AUTOSAR XML (schema 00048)
package /myproject/Application/Executable
  executable IAMApp01Exe: category=APPLICATION_LEVEL, build-type=BUILD-TYPE-DEBUG, logging-behavior=USES-LOGGING, reporting-behavior=REPORTS-EXECUTION-STATE
    root sw component prototype RootSwComponent: application-type=IAMApp01
package /myproject/Application/Process
  process IAMApp01_process: design=IAMApp01_processDesign, executable=IAMApp01Exe, log-trace-default-log-level=DEBUG, log-trace-file-path=/adar/install/var/log_apps/ECU1/IAMApp01, log-trace-log-modes=[CONSOLE, FILE, NETWORK], log-trace-process-desc=IAMApp01, log-trace-process-id=IAM1, state-dependent-startup-config{function-group-state=MachineState.Driving, startup-config=startup_config}
    process state machine ProcessStateMachine: type=ProcessState
package /myproject/Application/ProcessDesign
  process design IAMApp01_processDesign: executable=IAMApp01Exe
package /myproject/Application/SwComponent
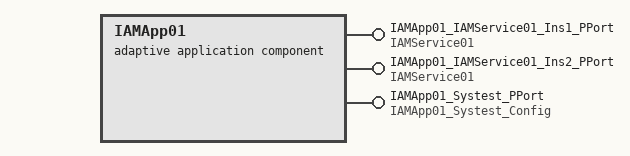
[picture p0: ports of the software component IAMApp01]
  adaptive application sw component type IAMApp01
    provide port IAMApp01_IAMService01_Ins1_PPort: provided-interface=IAMService01
      provided-com-specs:
        queued-sender-com-spec={data-element=Event01, sender-capability=WILL-SEND}
        field-sender-com-spec={data-element=Field01, sender-capability=WILL-SEND}
    provide port IAMApp01_IAMService01_Ins2_PPort: provided-interface=IAMService01
      provided-com-specs:
        queued-sender-com-spec={data-element=Event01, sender-capability=WILL-SEND}
        field-sender-com-spec={data-element=Field01, sender-capability=WILL-SEND}
    provide port IAMApp01_Systest_PPort: provided-interface=IAMApp01_Systest_Config
package /myproject/Service
  someip sd client event group timing config client_timingConf_1: request-response-delay={max-value=0.5, min-value=0.0}, subscribe-eventgroup-retry-delay=10.0, subscribe-eventgroup-retry-max=10, time-to-live=10
package /myproject/Service/IAMService01
  someip service instance to machine mapping IAMApp01_IAMService01_Ins1_ProvidedServiceInstance_toMachine: communication-connector=ECU1CommunicationConnector, service-instance=IAMApp01_IAMService01_Ins1_Provided_Instance, udp-port=1
  service instance to port prototype mapping IAMApp01_IAMService01_Ins1_ProvidedServiceInstance_toPort: port-prototype=IAMApp01_IAMService01_Ins1_PPort, process=IAMApp01_processDesign, service-instance=IAMApp01_IAMService01_Ins1_Provided_Instance
  provided someip service instance IAMApp01_IAMService01_Ins1_Provided_Instance: service-interface-deployment=IAMService01_Dep, event-propss=[Someip_Event01Dep, Someip_Field01Dep_Notifier], method-response-propss=[Someip_Method01Dep, Someip_Field01Dep_Getter, Someip_Field01Dep_Setter], service-instance-id=1
    someip provided event group SomeipPEventGroup_1: event-group=EventGroup_1, event-multicast-udp-port=0, ipv-4-multicast-ip-address=0.0.0.0, ipv-6-multicast-ip-address=0:0:0:0:0:0:0:0, multicast-threshold=0
    someip provided event group SomeipPEventGroup_2: event-group=EventGroup_2, event-multicast-udp-port=0, ipv-4-multicast-ip-address=0.0.0.0, ipv-6-multicast-ip-address=0:0:0:0:0:0:0:0, multicast-threshold=0
  someip service instance to machine mapping IAMApp01_IAMService01_Ins2_ProvidedServiceInstance_toMachine: communication-connector=ECU1CommunicationConnector, service-instance=IAMApp01_IAMService01_Ins2_Provided_Instance, udp-port=2
  service instance to port prototype mapping IAMApp01_IAMService01_Ins2_ProvidedServiceInstance_toPort: port-prototype=IAMApp01_IAMService01_Ins2_PPort, process=IAMApp01_processDesign, service-instance=IAMApp01_IAMService01_Ins2_Provided_Instance
  provided someip service instance IAMApp01_IAMService01_Ins2_Provided_Instance: service-interface-deployment=IAMService01_Dep, event-propss=[Someip_Event01Dep, Someip_Field01Dep_Notifier], method-response-propss=[Someip_Method01Dep, Someip_Field01Dep_Getter, Someip_Field01Dep_Setter], service-instance-id=2
    someip provided event group SomeipPEventGroup_1: event-group=EventGroup_1, event-multicast-udp-port=0, ipv-4-multicast-ip-address=0.0.0.0, ipv-6-multicast-ip-address=0:0:0:0:0:0:0:0, multicast-threshold=0
    someip provided event group SomeipPEventGroup_2: event-group=EventGroup_2, event-multicast-udp-port=0, ipv-4-multicast-ip-address=0.0.0.0, ipv-6-multicast-ip-address=0:0:0:0:0:0:0:0, multicast-threshold=0
package /myproject/Service/Systest
  someip service instance to machine mapping IAMApp01_Systest_ProvidedServiceInstance_toMachine: communication-connector=ECU1CommunicationConnector, service-instance=IAMApp01_Systest_Provided_Instance, udp-port=31401
  service instance to port prototype mapping IAMApp01_Systest_ProvidedServiceInstance_toPort: port-prototype=IAMApp01_Systest_PPort, process=IAMApp01_processDesign, service-instance=IAMApp01_Systest_Provided_Instance
  provided someip service instance IAMApp01_Systest_Provided_Instance: service-interface-deployment=IAMApp01_Systest_Config_Dep, someip-method-props=Someip_StartOfferServiceDep, service-instance-id=1
package /myproject/System/ProcessToMachineMappingSet
  process to machine mapping set IAMApp01procToMachineMappingSet
    process to machine mapping procToMachineMapping: machine=ECU1Machine, process=IAMApp01_process
package /myproject/System/StartupConfigSet
  startup config set IAMApp01_startup_set
    startup config startup_config: scheduling-policy=SCHEDULING-POLICY-ROUND-ROBIN, scheduling-priority=12, timeout={enter-timeout-value=3.0, exit-timeout-value=3.0}
